AUTOSAR XML (schema 4-0-3)
package /ComponentTypes
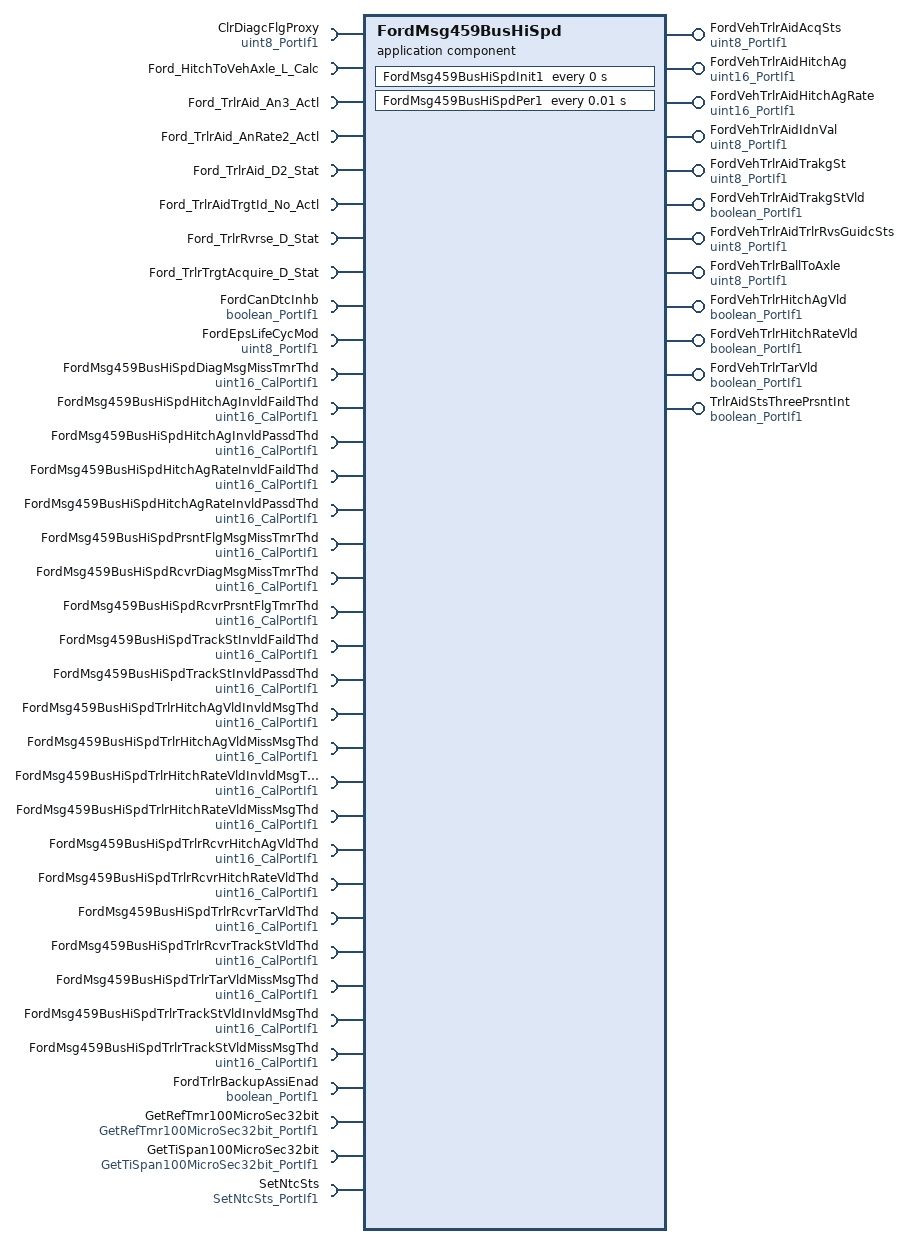
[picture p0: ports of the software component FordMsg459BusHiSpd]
  application sw component type FordMsg459BusHiSpd
    12 x provide port:
      FordVehTrlrAidAcqSts: nonqueued-sender-com-spec{data-element=Val, init-value=0}, provided-interface=uint8_PortIf1
      FordVehTrlrAidHitchAg: nonqueued-sender-com-spec{data-element=Val, init-value=720}, provided-interface=uint16_PortIf1
      FordVehTrlrAidHitchAgRate: nonqueued-sender-com-spec{data-element=Val, init-value=400}, provided-interface=uint16_PortIf1
      FordVehTrlrAidIdnVal: nonqueued-sender-com-spec{data-element=Val, init-value=0}, provided-interface=uint8_PortIf1
      FordVehTrlrAidTrakgSt: nonqueued-sender-com-spec{data-element=Val, init-value=0}, provided-interface=uint8_PortIf1
      FordVehTrlrAidTrakgStVld: nonqueued-sender-com-spec{data-element=Logl, init-value=0}, provided-interface=boolean_PortIf1
      FordVehTrlrAidTrlrRvsGuidcSts: nonqueued-sender-com-spec{data-element=Val, init-value=0}, provided-interface=uint8_PortIf1
      FordVehTrlrBallToAxle: nonqueued-sender-com-spec{data-element=Val, init-value=255}, provided-interface=uint8_PortIf1
      FordVehTrlrHitchAgVld: nonqueued-sender-com-spec{data-element=Logl, init-value=0}, provided-interface=boolean_PortIf1
      FordVehTrlrHitchRateVld: nonqueued-sender-com-spec{data-element=Logl, init-value=0}, provided-interface=boolean_PortIf1
      FordVehTrlrTarVld: nonqueued-sender-com-spec{data-element=Logl, init-value=0}, provided-interface=boolean_PortIf1
      TrlrAidStsThreePrsntInt: nonqueued-sender-com-spec{data-element=Logl, init-value=0}, provided-interface=boolean_PortIf1
    35 x require port:
      ClrDiagcFlgProxy: nonqueued-receiver-com-spec{data-element=Val, filter=data-filter-type=ALWAYS, init-value=0}, required-interface=uint8_PortIf1
      Ford_HitchToVehAxle_L_Calc: nonqueued-receiver-com-spec{data-element=Ford_HitchToVehAxle_L_Calc, filter=data-filter-type=ALWAYS, init-value=255}, required-interface=Ford_HitchToVehAxle_L_Calc
      Ford_TrlrAid_An3_Actl: nonqueued-receiver-com-spec{data-element=Ford_TrlrAid_An3_Actl, filter=data-filter-type=ALWAYS, init-value=720}, required-interface=Ford_TrlrAid_An3_Actl
      Ford_TrlrAid_AnRate2_Actl: nonqueued-receiver-com-spec{data-element=Ford_TrlrAid_AnRate2_Actl, filter=data-filter-type=ALWAYS, init-value=400}, required-interface=Ford_TrlrAid_AnRate2_Actl
      Ford_TrlrAid_D2_Stat: nonqueued-receiver-com-spec{data-element=Ford_TrlrAid_D2_Stat, filter=data-filter-type=ALWAYS, init-value=0}, required-interface=Ford_TrlrAid_D2_Stat
      Ford_TrlrAidTrgtId_No_Actl: nonqueued-receiver-com-spec{data-element=Ford_TrlrAidTrgtId_No_Actl, filter=data-filter-type=ALWAYS, init-value=0}, required-interface=Ford_TrlrAidTrgtId_No_Actl
      Ford_TrlrRvrse_D_Stat: nonqueued-receiver-com-spec{data-element=Ford_TrlrRvrse_D_Stat, filter=data-filter-type=ALWAYS, init-value=0}, required-interface=Ford_TrlrRvrse_D_Stat
      Ford_TrlrTrgtAcquire_D_Stat: nonqueued-receiver-com-spec{data-element=Ford_TrlrTrgtAcquire_D_Stat, filter=data-filter-type=ALWAYS, init-value=0}, required-interface=Ford_TrlrTrgtAcquire_D_Stat
      FordCanDtcInhb: nonqueued-receiver-com-spec{data-element=Logl, filter=data-filter-type=ALWAYS, init-value=1}, required-interface=boolean_PortIf1
      FordEpsLifeCycMod: nonqueued-receiver-com-spec{data-element=Val, filter=data-filter-type=ALWAYS, init-value=0}, required-interface=uint8_PortIf1
      FordMsg459BusHiSpdDiagMsgMissTmrThd: parameter-require-com-spec{init-value=5000, parameter=Val}, required-interface=uint16_CalPortIf1
      FordMsg459BusHiSpdHitchAgInvldFaildThd: parameter-require-com-spec{init-value=0, parameter=Val}, required-interface=uint16_CalPortIf1
      FordMsg459BusHiSpdHitchAgInvldPassdThd: parameter-require-com-spec{init-value=0, parameter=Val}, required-interface=uint16_CalPortIf1
      FordMsg459BusHiSpdHitchAgRateInvldFaildThd: parameter-require-com-spec{init-value=0, parameter=Val}, required-interface=uint16_CalPortIf1
      FordMsg459BusHiSpdHitchAgRateInvldPassdThd: parameter-require-com-spec{init-value=0, parameter=Val}, required-interface=uint16_CalPortIf1
      FordMsg459BusHiSpdPrsntFlgMsgMissTmrThd: parameter-require-com-spec{init-value=5000, parameter=Val}, required-interface=uint16_CalPortIf1
      FordMsg459BusHiSpdRcvrDiagMsgMissTmrThd: parameter-require-com-spec{init-value=0, parameter=Val}, required-interface=uint16_CalPortIf1
      FordMsg459BusHiSpdRcvrPrsntFlgTmrThd: parameter-require-com-spec{init-value=0, parameter=Val}, required-interface=uint16_CalPortIf1
      FordMsg459BusHiSpdTrackStInvldFaildThd: parameter-require-com-spec{init-value=0, parameter=Val}, required-interface=uint16_CalPortIf1
      FordMsg459BusHiSpdTrackStInvldPassdThd: parameter-require-com-spec{init-value=0, parameter=Val}, required-interface=uint16_CalPortIf1
      FordMsg459BusHiSpdTrlrHitchAgVldInvldMsgThd: parameter-require-com-spec{init-value=0, parameter=Val}, required-interface=uint16_CalPortIf1
      FordMsg459BusHiSpdTrlrHitchAgVldMissMsgThd: parameter-require-com-spec{init-value=5000, parameter=Val}, required-interface=uint16_CalPortIf1
      FordMsg459BusHiSpdTrlrHitchRateVldInvldMsgThd: parameter-require-com-spec{init-value=0, parameter=Val}, required-interface=uint16_CalPortIf1
      FordMsg459BusHiSpdTrlrHitchRateVldMissMsgThd: parameter-require-com-spec{init-value=5000, parameter=Val}, required-interface=uint16_CalPortIf1
      FordMsg459BusHiSpdTrlrRcvrHitchAgVldThd: parameter-require-com-spec{init-value=0, parameter=Val}, required-interface=uint16_CalPortIf1
      FordMsg459BusHiSpdTrlrRcvrHitchRateVldThd: parameter-require-com-spec{init-value=5000, parameter=Val}, required-interface=uint16_CalPortIf1
      FordMsg459BusHiSpdTrlrRcvrTarVldThd: parameter-require-com-spec{init-value=0, parameter=Val}, required-interface=uint16_CalPortIf1
      FordMsg459BusHiSpdTrlrRcvrTrackStVldThd: parameter-require-com-spec{init-value=0, parameter=Val}, required-interface=uint16_CalPortIf1
      FordMsg459BusHiSpdTrlrTarVldMissMsgThd: parameter-require-com-spec{init-value=0, parameter=Val}, required-interface=uint16_CalPortIf1
      FordMsg459BusHiSpdTrlrTrackStVldInvldMsgThd: parameter-require-com-spec{init-value=0, parameter=Val}, required-interface=uint16_CalPortIf1
      FordMsg459BusHiSpdTrlrTrackStVldMissMsgThd: parameter-require-com-spec{init-value=0, parameter=Val}, required-interface=uint16_CalPortIf1
      FordTrlrBackupAssiEnad: nonqueued-receiver-com-spec{data-element=Logl, filter=data-filter-type=ALWAYS, init-value=0}, required-interface=boolean_PortIf1
      GetRefTmr100MicroSec32bit: client-com-spec=Oper, required-interface=GetRefTmr100MicroSec32bit_PortIf1
      GetTiSpan100MicroSec32bit: client-com-spec=Oper, required-interface=GetTiSpan100MicroSec32bit_PortIf1
      SetNtcSts: client-com-spec=Oper, required-interface=SetNtcSts_PortIf1
    behavior FordMsg459BusHiSpd_InternalBehavior
      ar-typed-per-instance-memorys:
        23 x data, all with sw-calibration-access=READ-ONLY:
          ClrDiagcFlgProxyPrev: type=uint8
          FirstTranVldFlg: type=boolean
          FordVehMsg459Miss: type=boolean
          FordVehMsg459MissTmr: type=uint32
          FordVehMsg459RxdTmr: type=uint32
          FordVehTrlrAidAcqStsPrev: type=uint8
          FordVehTrlrAidGuidcRevsStsPrev: type=uint8
          FordVehTrlrAidHitchAgPrev: type=uint16
          FordVehTrlrAidHitchAgRatePrev: type=uint16
          FordVehTrlrAidIdnValPrev: type=uint8
          FordVehTrlrAidTrackStFaildTmr: type=uint32
          FordVehTrlrAidTrackStPassdTmr: type=uint32
          FordVehTrlrAidTrackStPrev: type=uint8
          FordVehTrlrBallToAxlePrev: type=uint8
          FordVehTrlrHitchAgFaildTmr: type=uint32
          FordVehTrlrHitchAgPassdTmr: type=uint32
          FordVehTrlrHitchAgRateFaildTmr: type=uint32
          FordVehTrlrHitchAgRatePassdTmr: type=uint32
          FordVehTrlrHitchAgVldPrev: type=boolean
          FordVehTrlrHitchRateVldPrev: type=boolean
          FordVehTrlrTarVldPrev: type=boolean
          FordVehTrlrTrackStVldPrev: type=boolean
          TrlrAidStsThreePrsntIntPrev: type=boolean
      timing event FordMsg459BusHiSpd_InitEvent: start-on-event=FordMsg459BusHiSpdInit1, period=0
      timing event TMT_FordMsg459BusHiSpdPer1: start-on-event=FordMsg459BusHiSpdPer1, period=0.01
      port-api-options:
        enable-take-address=false, indirect-api=false, port=ClrDiagcFlgProxy
        enable-take-address=false, indirect-api=false, port=Ford_HitchToVehAxle_L_Calc
        enable-take-address=false, indirect-api=false, port=Ford_TrlrAid_An3_Actl
        enable-take-address=false, indirect-api=false, port=Ford_TrlrAid_AnRate2_Actl
        enable-take-address=false, indirect-api=false, port=Ford_TrlrAid_D2_Stat
        enable-take-address=false, indirect-api=false, port=Ford_TrlrAidTrgtId_No_Actl
        enable-take-address=false, indirect-api=false, port=Ford_TrlrRvrse_D_Stat
        enable-take-address=false, indirect-api=false, port=Ford_TrlrTrgtAcquire_D_Stat
        enable-take-address=false, indirect-api=false, port=FordCanDtcInhb
        enable-take-address=false, indirect-api=false, port=FordEpsLifeCycMod
        enable-take-address=false, indirect-api=false, port=FordMsg459BusHiSpdDiagMsgMissTmrThd
        enable-take-address=false, indirect-api=false, port=FordMsg459BusHiSpdHitchAgInvldFaildThd
        enable-take-address=false, indirect-api=false, port=FordMsg459BusHiSpdHitchAgInvldPassdThd
        enable-take-address=false, indirect-api=false, port=FordMsg459BusHiSpdHitchAgRateInvldFaildThd
        enable-take-address=false, indirect-api=false, port=FordMsg459BusHiSpdHitchAgRateInvldPassdThd
        enable-take-address=false, indirect-api=false, port=FordMsg459BusHiSpdPrsntFlgMsgMissTmrThd
        enable-take-address=false, indirect-api=false, port=FordMsg459BusHiSpdRcvrDiagMsgMissTmrThd
        enable-take-address=false, indirect-api=false, port=FordMsg459BusHiSpdRcvrPrsntFlgTmrThd
        enable-take-address=false, indirect-api=false, port=FordMsg459BusHiSpdTrackStInvldFaildThd
        enable-take-address=false, indirect-api=false, port=FordMsg459BusHiSpdTrackStInvldPassdThd
        enable-take-address=false, indirect-api=false, port=FordMsg459BusHiSpdTrlrHitchAgVldInvldMsgThd
        enable-take-address=false, indirect-api=false, port=FordMsg459BusHiSpdTrlrHitchAgVldMissMsgThd
        enable-take-address=false, indirect-api=false, port=FordMsg459BusHiSpdTrlrHitchRateVldInvldMsgThd
        enable-take-address=false, indirect-api=false, port=FordMsg459BusHiSpdTrlrHitchRateVldMissMsgThd
        enable-take-address=false, indirect-api=false, port=FordMsg459BusHiSpdTrlrRcvrHitchAgVldThd
        enable-take-address=false, indirect-api=false, port=FordMsg459BusHiSpdTrlrRcvrHitchRateVldThd
        enable-take-address=false, indirect-api=false, port=FordMsg459BusHiSpdTrlrRcvrTarVldThd
        enable-take-address=false, indirect-api=false, port=FordMsg459BusHiSpdTrlrRcvrTrackStVldThd
        enable-take-address=false, indirect-api=false, port=FordMsg459BusHiSpdTrlrTarVldMissMsgThd
        enable-take-address=false, indirect-api=false, port=FordMsg459BusHiSpdTrlrTrackStVldInvldMsgThd
        enable-take-address=false, indirect-api=false, port=FordMsg459BusHiSpdTrlrTrackStVldMissMsgThd
        enable-take-address=false, indirect-api=false, port=FordTrlrBackupAssiEnad
        enable-take-address=false, indirect-api=false, port=FordVehTrlrAidAcqSts
        enable-take-address=false, indirect-api=false, port=FordVehTrlrAidHitchAg
        enable-take-address=false, indirect-api=false, port=FordVehTrlrAidHitchAgRate
        enable-take-address=false, indirect-api=false, port=FordVehTrlrAidIdnVal
        enable-take-address=false, indirect-api=false, port=FordVehTrlrAidTrakgSt
        enable-take-address=false, indirect-api=false, port=FordVehTrlrAidTrakgStVld
        enable-take-address=false, indirect-api=false, port=FordVehTrlrAidTrlrRvsGuidcSts
        enable-take-address=false, indirect-api=false, port=FordVehTrlrBallToAxle
        enable-take-address=false, indirect-api=false, port=FordVehTrlrHitchAgVld
        enable-take-address=false, indirect-api=false, port=FordVehTrlrHitchRateVld
        enable-take-address=false, indirect-api=false, port=FordVehTrlrTarVld
        enable-take-address=false, indirect-api=false, port=GetRefTmr100MicroSec32bit
        enable-take-address=false, indirect-api=false, port=GetTiSpan100MicroSec32bit
        enable-take-address=false, indirect-api=false, port=SetNtcSts
        enable-take-address=false, indirect-api=false, port=TrlrAidStsThreePrsntInt
      runnable FordMsg459BusHiSpdInit1
        sync call SC_GetRefTmr100MicroSec32bit_Oper: operation=GetRefTmr100MicroSec32bit.Oper, timeout=0
      runnable FordMsg459BusHiSpdPer1
        data-receive-point-by-arguments:
          11 x access:
            REC_ClrDiagcFlgProxy_Val: accessed-variable=ClrDiagcFlgProxy.Val
            REC_Ford_HitchToVehAxle_L_Calc_Ford_HitchToVehAxle_L_Calc: accessed-variable=Ford_HitchToVehAxle_L_Calc.Ford_HitchToVehAxle_L_Calc
            REC_Ford_TrlrAid_An3_Actl_Ford_TrlrAid_An3_Actl: accessed-variable=Ford_TrlrAid_An3_Actl.Ford_TrlrAid_An3_Actl
            REC_Ford_TrlrAid_AnRate2_Actl_Ford_TrlrAid_AnRate2_Actl: accessed-variable=Ford_TrlrAid_AnRate2_Actl.Ford_TrlrAid_AnRate2_Actl
            REC_Ford_TrlrAid_D2_Stat_Ford_TrlrAid_D2_Stat: accessed-variable=Ford_TrlrAid_D2_Stat.Ford_TrlrAid_D2_Stat
            REC_Ford_TrlrAidTrgtId_No_Actl_Ford_TrlrAidTrgtId_No_Actl: accessed-variable=Ford_TrlrAidTrgtId_No_Actl.Ford_TrlrAidTrgtId_No_Actl
            REC_Ford_TrlrRvrse_D_Stat_Ford_TrlrRvrse_D_Stat: accessed-variable=Ford_TrlrRvrse_D_Stat.Ford_TrlrRvrse_D_Stat
            REC_Ford_TrlrTrgtAcquire_D_Stat_Ford_TrlrTrgtAcquire_D_Stat: accessed-variable=Ford_TrlrTrgtAcquire_D_Stat.Ford_TrlrTrgtAcquire_D_Stat
            REC_FordCanDtcInhb_Logl: accessed-variable=FordCanDtcInhb.Logl
            REC_FordEpsLifeCycMod_Val: accessed-variable=FordEpsLifeCycMod.Val
            REC_FordTrlrBackupAssiEnad_Logl: accessed-variable=FordTrlrBackupAssiEnad.Logl
        data-send-points:
          12 x access:
            SEND_FordVehTrlrAidAcqSts_Val: accessed-variable=FordVehTrlrAidAcqSts.Val
            SEND_FordVehTrlrAidHitchAg_Val: accessed-variable=FordVehTrlrAidHitchAg.Val
            SEND_FordVehTrlrAidHitchAgRate_Val: accessed-variable=FordVehTrlrAidHitchAgRate.Val
            SEND_FordVehTrlrAidIdnVal_Val: accessed-variable=FordVehTrlrAidIdnVal.Val
            SEND_FordVehTrlrAidTrakgSt_Val: accessed-variable=FordVehTrlrAidTrakgSt.Val
            SEND_FordVehTrlrAidTrakgStVld_Logl: accessed-variable=FordVehTrlrAidTrakgStVld.Logl
            SEND_FordVehTrlrAidTrlrRvsGuidcSts_Val: accessed-variable=FordVehTrlrAidTrlrRvsGuidcSts.Val
            SEND_FordVehTrlrBallToAxle_Val: accessed-variable=FordVehTrlrBallToAxle.Val
            SEND_FordVehTrlrHitchAgVld_Logl: accessed-variable=FordVehTrlrHitchAgVld.Logl
            SEND_FordVehTrlrHitchRateVld_Logl: accessed-variable=FordVehTrlrHitchRateVld.Logl
            SEND_FordVehTrlrTarVld_Logl: accessed-variable=FordVehTrlrTarVld.Logl
            SEND_TrlrAidStsThreePrsntInt_Logl: accessed-variable=TrlrAidStsThreePrsntInt.Logl
        sync call SC_GetRefTmr100MicroSec32bit_Oper: operation=GetRefTmr100MicroSec32bit.Oper, timeout=0
        sync call SC_GetTiSpan100MicroSec32bit_Oper: operation=GetTiSpan100MicroSec32bit.Oper, timeout=0
        sync call SC_SetNtcSts_Oper: operation=SetNtcSts.Oper, timeout=0
  swc implementation FordMsg459BusHiSpd_Implementation: behavior=FordMsg459BusHiSpd_InternalBehavior
    code-descriptors:
      code Default: artifact-descriptors=autosar-engineering-object={short-label=Default, category=SWSRC}
